AUTOSAR XML (schema 4-0-3)
package /ComponentTypes
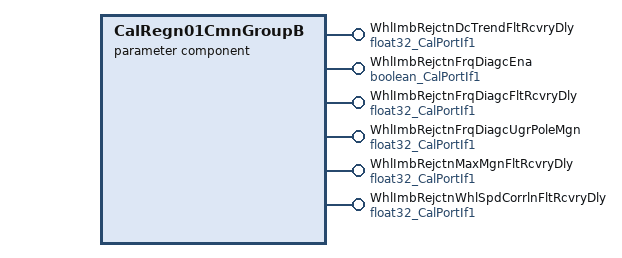
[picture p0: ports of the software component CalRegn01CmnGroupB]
  parameter sw component type CalRegn01CmnGroupB
    6 x provide port:
      WhlImbRejctnDcTrendFltRcvryDly: parameter-provide-com-spec{init-value=5, parameter=Val}, provided-interface=float32_CalPortIf1
      WhlImbRejctnFrqDiagcEna: parameter-provide-com-spec{init-value=1, parameter=Logl}, provided-interface=boolean_CalPortIf1
      WhlImbRejctnFrqDiagcFltRcvryDly: parameter-provide-com-spec{init-value=5, parameter=Val}, provided-interface=float32_CalPortIf1
      WhlImbRejctnFrqDiagcUgrPoleMgn: parameter-provide-com-spec{init-value=0.949997, parameter=Val}, provided-interface=float32_CalPortIf1
      WhlImbRejctnMaxMgnFltRcvryDly: parameter-provide-com-spec{init-value=5, parameter=Val}, provided-interface=float32_CalPortIf1
      WhlImbRejctnWhlSpdCorrlnFltRcvryDly: parameter-provide-com-spec{init-value=5, parameter=Val}, provided-interface=float32_CalPortIf1
